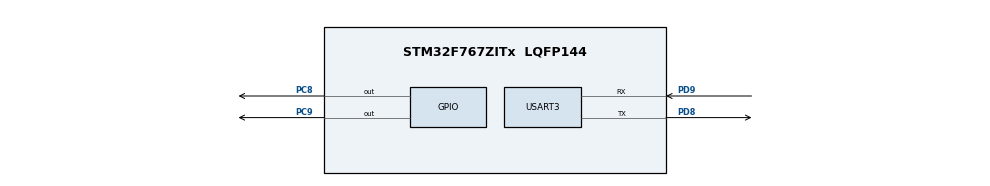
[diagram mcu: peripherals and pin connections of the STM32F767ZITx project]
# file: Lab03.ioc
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Mcu.Family=STM32F7
Mcu.Name=STM32F767ZITx
Mcu.Package=LQFP144
NVIC.PriorityGroup=NVIC_PRIORITYGROUP_4
PC8.Signal=GPIO_Output
PC9.Signal=GPIO_Output
PD8.Mode=Asynchronous
PD8.Signal=USART3_TX
PD9.Mode=Asynchronous
PD9.Signal=USART3_RX
ProjectManager.HeapSize=0x200
ProjectManager.StackSize=0x400
ProjectManager.TargetToolchain=STM32CubeIDE
RCC.HSE_VALUE=25000000
RCC.HSI_VALUE=16000000
RCC.LSE_VALUE=32768
RCC.USBFreq_Value=96000000
RCC.VCOOutputFreq_Value=192000000
USART3.VirtualMode-Asynchronous=VM_ASYNC
board=custom

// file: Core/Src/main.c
/* USER CODE BEGIN Header */
/**
 ******************************************************************************
 * @file           : main.c
 * @brief          : Main program body
 ******************************************************************************
 * @attention
 *
 * Copyright (c) 2022 STMicroelectronics.
 * All rights reserved.
 *
 * This software is licensed under terms that can be found in the LICENSE file
 * in the root directory of this software component.
 * If no LICENSE file comes with this software, it is provided AS-IS.
 *
 ******************************************************************************
 */
/* USER CODE END Header */
#include "main.h"
#include "usart.h"
#include "gpio.h"

/* USER CODE BEGIN Includes */
#include "string.h"
/* USER CODE END Includes */

/* USER CODE BEGIN PV */
char ch1;
uint8_t state = 0;
/* USER CODE END PV */

void SystemClock_Config(void);

int main(void) {

	/* MCU Configuration--------------------------------------------------------*/

	/* Reset of all peripherals, Initializes the Flash interface and the Systick. */
	HAL_Init();

	/* Configure the system clock */
	SystemClock_Config();

	/* Initialize all configured peripherals */
	MX_GPIO_Init();
	MX_USART3_UART_Init();

	/* Infinite loop */
	while (1) {
//		char ch1 = 'A';
//		HAL_UART_Transmit(&huart3, (uint8_t*) &ch1, 1, 1000);

//		char str[] = "Input => ";
//		if (state == 0)
//		{
//			while (__HAL_UART_GET_FLAG(&huart3,UART_FLAG_TC) == RESET) {
//						}
//						HAL_UART_Transmit(&huart3, (uint8_t*) str, strlen(str), 1000);
//						while (__HAL_UART_GET_FLAG(&huart3,UART_FLAG_RXNE) == RESET) {
//						}
//						HAL_UART_Receive(&huart3, (uint8_t*) &ch1, 1, 1000);
//						while (__HAL_UART_GET_FLAG(&huart3,UART_FLAG_TC) == RESET) {
//						}
//						HAL_UART_Transmit(&huart3, (uint8_t*) &ch1, 1, 1000);
//						HAL_UART_Transmit(&huart3, "\n\r", 2, 1000);
//						state = 1;
//		}
//		if (state == 1)
//		{
//
//			state = 2;
//		}

		char str[] = "\tInput => ";
		char text1[] =
				"Display Blinking LED PRESS (1, 2)\n\rDisplay Group Members PRESS m\n\rQuit PRESS q\n\r";
		HAL_GPIO_WritePin(GPIOC, GPIO_PIN_8, 1);
		HAL_GPIO_WritePin(GPIOC, GPIO_PIN_9, 1);
		if (state == 0) { //start state = 0

			while (__HAL_UART_GET_FLAG(&huart3,UART_FLAG_TC) == RESET) {
			}
			HAL_UART_Transmit(&huart3, (uint8_t*) text1, strlen(text1), 1000);
			HAL_UART_Transmit(&huart3, (uint8_t*) str, strlen(str), 1000);
			while (__HAL_UART_GET_FLAG(&huart3,UART_FLAG_RXNE) == RESET) {
			}
			HAL_UART_Receive(&huart3, (uint8_t*) &ch1, 1, 1000);
			while (__HAL_UART_GET_FLAG(&huart3,UART_FLAG_TC) == RESET) {
			}
			HAL_UART_Transmit(&huart3, (uint8_t*) &ch1, 1, 1000);
			HAL_UART_Transmit(&huart3, "\n\r", 2, 1000);
			state = 2;
		} else if (state == 1) {
			while (__HAL_UART_GET_FLAG(&huart3,UART_FLAG_TC) == RESET) {
			}
			HAL_UART_Transmit(&huart3, (uint8_t*) str, strlen(str), 1000);
			while (__HAL_UART_GET_FLAG(&huart3,UART_FLAG_RXNE) == RESET) {
			}
			HAL_UART_Receive(&huart3, (uint8_t*) &ch1, 1, 1000);
			while (__HAL_UART_GET_FLAG(&huart3,UART_FLAG_TC) == RESET) {
			}
			HAL_UART_Transmit(&huart3, (uint8_t*) &ch1, 1, 1000);
			HAL_UART_Transmit(&huart3, "\n\r", 2, 1000);
			state = 2;
		}
		if (ch1 == '1' && state == 2) {
			for (int i = 0; i < 3; i++) {
				HAL_GPIO_WritePin(GPIOC, GPIO_PIN_8, 0);
				HAL_Delay(300);
				HAL_GPIO_WritePin(GPIOC, GPIO_PIN_8, 1);
				HAL_Delay(300);
			}
			state = 1;
		} else if (ch1 == '2' && state == 2) {
			for (int i = 0; i < 3; i++) {
				HAL_GPIO_WritePin(GPIOC, GPIO_PIN_9, 0);
				HAL_Delay(300);
				HAL_GPIO_WritePin(GPIOC, GPIO_PIN_9, 1);
				HAL_Delay(300);
			}
			state = 1;
		} else if (ch1 == 'm' && state == 2) {
			char name[] = "63010631\n\rPhacharaphol Chokkhun\n\r";
			while (__HAL_UART_GET_FLAG(&huart3,UART_FLAG_TC) == RESET) {
			}
			HAL_UART_Transmit(&huart3, (uint8_t*) name, strlen(name), 1000);
			state = 1;
		} else if (ch1 != '1' && ch1 != '2' && ch1 != 'm' && ch1 != 'q'
				&& state == 2) {
			char unknow[] = "Unknow Command\n\r";
			while (__HAL_UART_GET_FLAG(&huart3,UART_FLAG_TC) == RESET) {
			}
			HAL_UART_Transmit(&huart3, (uint8_t*) unknow, strlen(unknow), 1000);
			state = 1;
		}
		if (ch1 == 'q' && state != 3) {
			while (__HAL_UART_GET_FLAG(&huart3,UART_FLAG_TC) == RESET) {
			}
			HAL_UART_Transmit(&huart3, "Quit", 4, 1000);
			state = 3;
		}
	}
}

void SystemClock_Config(void) {
	RCC_OscInitTypeDef RCC_OscInitStruct = { 0 };
	RCC_ClkInitTypeDef RCC_ClkInitStruct = { 0 };

	/** Configure the main internal regulator output voltage
	 */
	__HAL_RCC_PWR_CLK_ENABLE();
	__HAL_PWR_VOLTAGESCALING_CONFIG(PWR_REGULATOR_VOLTAGE_SCALE3);

	/** Initializes the RCC Oscillators according to the specified parameters
	 * in the RCC_OscInitTypeDef structure.
	 */
	RCC_OscInitStruct.OscillatorType = RCC_OSCILLATORTYPE_HSI;
	RCC_OscInitStruct.HSIState = RCC_HSI_ON;
	RCC_OscInitStruct.HSICalibrationValue = RCC_HSICALIBRATION_DEFAULT;
	RCC_OscInitStruct.PLL.PLLState = RCC_PLL_NONE;
	if (HAL_RCC_OscConfig(&RCC_OscInitStruct) != HAL_OK) {
		Error_Handler();
	}

	/** Initializes the CPU, AHB and APB buses clocks
	 */
	RCC_ClkInitStruct.ClockType = RCC_CLOCKTYPE_HCLK | RCC_CLOCKTYPE_SYSCLK
			| RCC_CLOCKTYPE_PCLK1 | RCC_CLOCKTYPE_PCLK2;
	RCC_ClkInitStruct.SYSCLKSource = RCC_SYSCLKSOURCE_HSI;
	RCC_ClkInitStruct.AHBCLKDivider = RCC_SYSCLK_DIV1;
	RCC_ClkInitStruct.APB1CLKDivider = RCC_HCLK_DIV1;
	RCC_ClkInitStruct.APB2CLKDivider = RCC_HCLK_DIV1;

	if (HAL_RCC_ClockConfig(&RCC_ClkInitStruct, FLASH_LATENCY_0) != HAL_OK) {
		Error_Handler();
	}
}

void Error_Handler(void) {
	__disable_irq();
	while (1) {
	}
}
